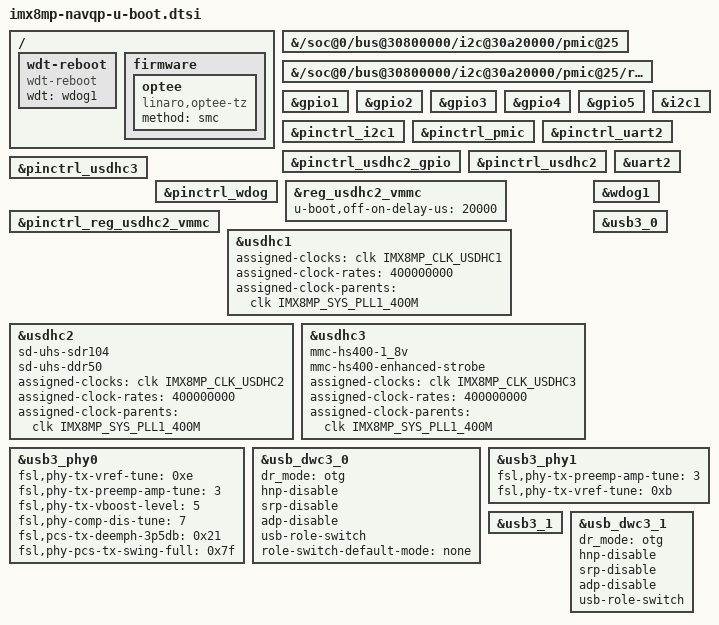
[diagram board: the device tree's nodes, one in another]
// SPDX-License-Identifier: GPL-2.0+
/*
 * Copyright 2019, 2021 NXP
 * Copyright 2024 Gilles Talis <gilles.talis@gmail.com>
 */

#include "imx8mp-u-boot.dtsi"

/ {
	wdt-reboot {
		compatible = "wdt-reboot";
		wdt = <&wdog1>;
		bootph-pre-ram;
	};

	firmware {
		optee {
			compatible = "linaro,optee-tz";
			method = "smc";
		};
	};
};

&{/soc@0/bus@30800000/i2c@30a20000/pmic@25} {
	bootph-all;
};

&{/soc@0/bus@30800000/i2c@30a20000/pmic@25/regulators} {
	bootph-all;
};

&gpio1 {
	bootph-pre-ram;
};

&gpio2 {
	bootph-pre-ram;
};

&gpio3 {
	bootph-pre-ram;
};

&gpio4 {
	bootph-pre-ram;
};

&gpio5 {
	bootph-pre-ram;
};

&i2c1 {
	bootph-all;
};

&pinctrl_i2c1 {
	bootph-pre-ram;
};

&pinctrl_pmic {
	bootph-pre-ram;
};

&pinctrl_uart2 {
	bootph-pre-ram;
};

&pinctrl_usdhc2_gpio {
	bootph-pre-ram;
};

&pinctrl_usdhc2 {
	bootph-pre-ram;
};

&pinctrl_usdhc3 {
	bootph-pre-ram;
};

&pinctrl_wdog {
	bootph-pre-ram;
};

&reg_usdhc2_vmmc {
	bootph-pre-ram;
	u-boot,off-on-delay-us = <20000>;
};

&pinctrl_reg_usdhc2_vmmc {
	bootph-pre-ram;
};

&uart2 {
	bootph-pre-ram;
};

&usdhc1 {
	bootph-pre-ram;
	assigned-clocks = <&clk IMX8MP_CLK_USDHC1>;
	assigned-clock-rates = <400000000>;
	assigned-clock-parents = <&clk IMX8MP_SYS_PLL1_400M>;
};

&usdhc2 {
	bootph-pre-ram;
	sd-uhs-sdr104;
	sd-uhs-ddr50;
	assigned-clocks = <&clk IMX8MP_CLK_USDHC2>;
	assigned-clock-rates = <400000000>;
	assigned-clock-parents = <&clk IMX8MP_SYS_PLL1_400M>;
};

&usdhc3 {
	bootph-pre-ram;
	mmc-hs400-1_8v;
	mmc-hs400-enhanced-strobe;
	assigned-clocks = <&clk IMX8MP_CLK_USDHC3>;
	assigned-clock-rates = <400000000>;
	assigned-clock-parents = <&clk IMX8MP_SYS_PLL1_400M>;
};

&wdog1 {
	bootph-pre-ram;
};

&usb3_phy0 {
	fsl,phy-tx-vref-tune = <0xe>;
	fsl,phy-tx-preemp-amp-tune = <3>;
	fsl,phy-tx-vboost-level = <5>;
	fsl,phy-comp-dis-tune = <7>;
	fsl,pcs-tx-deemph-3p5db = <0x21>;
	fsl,phy-pcs-tx-swing-full = <0x7f>;
	status = "okay";
};

&usb3_0 {
	status = "okay";
};

&usb_dwc3_0 {
	dr_mode = "otg";
	hnp-disable;
	srp-disable;
	adp-disable;
	usb-role-switch;
	role-switch-default-mode = "none";
	status = "okay";
};

&usb3_phy1 {
	fsl,phy-tx-preemp-amp-tune = <3>;
	fsl,phy-tx-vref-tune = <0xb>;
	status = "okay";
};

&usb3_1 {
	status = "okay";
};

&usb_dwc3_1 {
        dr_mode = "otg";
        hnp-disable;
        srp-disable;
        adp-disable;
        usb-role-switch;
        status = "okay";
};
